# NM1500_v1 register map
File version: 1.0
Registers are 32-bit, read-write, reset 0x0 unless marked. A register's access mark holds for its fields unless they carry their own. Offsets are from the block's base; [hi:lo] are bit positions; {n}, {i} and the like mark numbered series; 'fields as' and 'values as' point back to an identical list.

## MDU0 — MDU Register Map
Base 0x401D0000
Same registers: MDU1 0x401D0400
0x00 Ia — Phase A Current Register, Represented in Q-15 Format
  [15:0] DATA — Motor Phase Current Data Register. This register stores the phase current data represented in Q-15 format. The MCU must update registers Ia, Ib and Ic in the beginning of a FOC process flow.
0x04 Ib — Phase A Current Register, Represented in Q-15 Format
  fields as Ia
0x08 Ic — Phase A Current Register, Represented in Q-15 Format
  fields as Ia
0x0C Ialfa — Clarke Transformation Output Register, the Current Along alpha-axis
  [15:0] DATA — Clarke Transformation Output Data Register. This data content is produced by Clarke Transformation function block and stored in Q-15 format. It is also writable by software.
0x10 Ibeta — Clarke Transformation Output Register, the Current Along alpha-axis
  fields as Ialfa
0x14 SIN — Trigonometric Value of SIN Register, Represented in Q-15 Format
  [15:0] DATA — Trigonometric Value of SIN / COS Data Register. The trigonometric value of SIN and COS, which is represented in Q-15 format, must be preset before operating Park and inverse Park transformation.
0x18 COS — Trigonometric Value of SIN Register, Represented in Q-15 Format
  fields as SIN
0x1C Id — Park Transformation Output Register, the Current Along d-axis.
  [15:0] DATA — Park Transformation Output Data Register. This data content is produced by Park Transformation function block and stored in Q-15 format. It is also writable by software.
0x20 Iq — Park Transformation Output Register, the Current Along d-axis.
  fields as Id
0x24 Id_CMD — PI_d Controller Command Input Register, Represented in Q-15 Format.
  [15:0] CMD — PI Controller Command Input Register. The register content stands for the PI controller command input. It must be normalized in Q-15 format.
0x28 Iq_CMD — PI_d Controller Command Input Register, Represented in Q-15 Format.
  fields as Id_CMD
0x2C KP_d — Parameter KP for PI_d Controller, Represented in 18-bit I2Q-15 (Q2.15) Format
  [17:0] DATA — PI Controller Parameter Register. The KP_d and KP_q stand for the proportional parameter of PI controller, the KI_d and KI_q stand for the integral parameter of PI controller. The register data value must be stored in Q-15 format.
0x30 KI_d — Parameter KP for PI_d Controller, Represented in 18-bit I2Q-15 (Q2.15) Format
  fields as KP_d
0x34 KP_q — Parameter KP for PI_d Controller, Represented in 18-bit I2Q-15 (Q2.15) Format
  fields as KP_d
0x38 KI_q — Parameter KP for PI_d Controller, Represented in 18-bit I2Q-15 (Q2.15) Format
  fields as KP_d
0x3C PI_dFW — PI_d Controller Feed Forward Data Register
  [15:0] DATA — PI Controller Feed Forward Data Register. Software presets the feed forward value of the PI controller in this register.
0x40 PI_qFW — PI_d Controller Feed Forward Data Register
  fields as PI_dFW
0x44 UI_d — D-axis I Control Output Data Register
  [15:0] DATA — Integral Controller Output Data Register. The PI function block content I (Integral) controller and P (Propotional) controller, and I controller output data will be used as the next PI control flow. Here is the register to save the output data of I controller and will update when PI controller finished once operation. Here, the register content is a Q-15 format value.
0x48 UI_q — D-axis I Control Output Data Register
  fields as UI_d
0x4C Vd — PI_d Controller Output of d-axis, Represented in Q-15 Format
  [15:0] DATA — PI Controller Output Data Register (Inverse Park Transformation Input). This data content is produced by PI controller function block and stored in Q-15 format. It is also writable by software.
0x50 Vq — PI_d Controller Output of d-axis, Represented in Q-15 Format
  fields as Vd
0x54 Valfa — Inverse Park Transformation Output, the Voltage Along the alpha-axis
  [15:0] DATA — Inverse Park Transformation Output Data Register. This data content is produced by inverse Park Transformation function block and stored in Q-15 format. It is also writable by software.
0x58 Vbeta — Inverse Park Transformation Output, the Voltage Along the alpha-axis
  fields as Valfa
{0x58+4i} Vref{i} (i=1..3) — Inverse Clarke Transformation Output Register
  [15:0] DATA — Inverse Clarke Transformation Output Data Register. This data content is produced by inverse Clarke Transformation function block and stored in Q-15 format. It is also writable by software.
0x68 SVPDATA0 — SVPWM output Data Register (it is an unsigned 16-bit value and denotes Taon time)
  [15:0] DATA — SVPWM Output Data Register. This data content is produced by SVPWM function block and stored in Q-15 format. It is also writable by software.
0x6C SVPDATA2 — SVPWM output Data Register (it is an unsigned 16-bit value and denotes Taon time)
  fields as SVPDATA0
0x70 SVPDATA4 — SVPWM output Data Register (it is an unsigned 16-bit value and denotes Taon time)
  fields as SVPDATA0
0x74 SVPDATA0N — An unsigned16-bit data Normalizes SVPDATA0 to PWMNORM and within the limit between PWMMAX and PWMMIN
  [15:0] DATA — Normalized SVPDATA Register. The SVPWM function block will normalizes the value of SVP0/2/4 to the range between 0000h and the value of PWMNORM and limit the PWM duty value within PWMMAX and PWMMIN. If SVPWM function block auto mode is active, each new SVPDATA0N/2N/4N will be reload to PWM unit 0 duty registers PWM0/2/4 after SVPWM operation is completed if PWMRUN and LOAD bits are enabled in PWM unit 0. Here, the register content is a 16-bit unsigned integer.
0x78 SVPDATA2N — An unsigned16-bit data Normalizes SVPDATA0 to PWMNORM and within the limit between PWMMAX and PWMMIN
  fields as SVPDATA0N
0x7C SVPDATA4N — An unsigned16-bit data Normalizes SVPDATA0 to PWMNORM and within the limit between PWMMAX and PWMMIN
  fields as SVPDATA0N
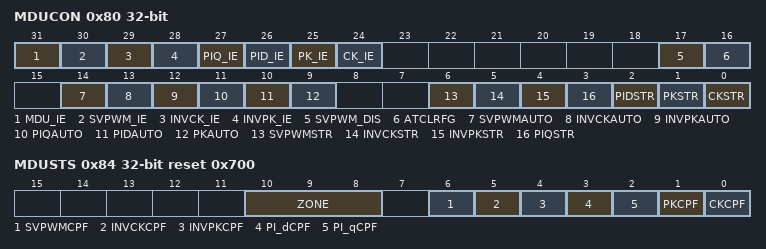
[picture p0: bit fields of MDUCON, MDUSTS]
0x80 MDUCON — Motor Driver Unit Control Register
  [31] MDU_IE — MDU Interrupt Enable Bit
    0=MDU interrupt Disabled; 1=MDU interrupt Enabled
  [30] SVPWM_IE — Clark Block Interrupt Enable Bit
    0=SVPWM block interrupt Disabled; 1=SVPWM block interrupt Enabled. Interrupt will generate if MDUINT_EN and SVPWM_IE is set to 1 and SVPWMCPF is set
  [29] INVCK_IE — Inv-Clark Block Interrupt Enable Bit
    0=Inv-Clark block interrupt Disabled; 1=Inv-Clark block interrupt Enabled
  [28] INVPK_IE — Inv-Park Block Interrupt Enable Bit
    0=Inv-Park block interrupt Disabled; 1=Inv-Park block interrupt Enabled
  [27] PIQ_IE — Q-axis PI Block Interrupt Enable Bit
    0=Q-axis PI controller block interrupt Disabled; 1=Q-axis PI controller block interrupt Enabled
  [26] PID_IE — D-axis PI Block Interrupt Enable Bit
    0=D-axis PI controller block interrupt Disabled; 1=D-axis PI controller block interrupt Enabled
  [25] PK_IE — Park Block Interrupt Enable Bit
    0=Park block interrupt Disabled; 1=Park block interrupt Enabled
  [24] CK_IE — Clark Block Interrupt Enable Bit
    0=Clark block interrupt Disabled; 1=Clark block interrupt Enabled
  [17] SVPWM_DIS — SVPWM Block Function Disable Bit
    0=SVPWM function block produces the Space Vector PWM timing for PWM duty registers; 1=SVPWM operation Disabled
  [16] ATCLRFG — Auto-Clear Flag Control Bit. When this bit is set to high, the complete flag of each function block in auto-mode is cleared automatically after SVPWM function block has updated PWM duty registers. The auto-clear flag function helps the FOC control flow runs smoothly without the need of software clearing flags.
    0=Auto-clear flag function Disabled; 1=Auto-clear flag function Enabled
  [14] SVPWMAUTO — SVPWM Auto-mode Enable Bit. Setting this bit will enable auto-mode of the function block. If the auto-mode is active, the SVPWM function block is allowed to accept the start trigger from Inverse Clarke block and SVPWM function proceeds completed, it will automatically update the duty registers in PWM unit0 and set the reload bit (LOAD).
    0=Auto-mode Disabled; 1=Auto-mode Enabled
  [13] INVCKAUTO — Inverse Clarke Transformation Auto-mode Enable Bit. Setting this bit will enable auto-mode of the function block. If the auto-mode is active, the current function block is allowed to accept the previous start trigger and will trigger the start bit of the next function block after current function is completed.
    0=Auto-mode Disabled; 1=Auto-mode Enabled
  [12] INVPKAUTO — Inverse Park Transformation Auto-mode Enable Bit. Setting this bit will enable auto-mode of the function block. If the auto-mode is active, the current function block is allowed to accept the previous start trigger and will trigger the start bit of the next function block after current function is completed.
    0=Auto-mode Disabled; 1=Auto-mode Enabled
  [11] PIQAUTO — D-axis PI Controller Auto-mode Enable Bit. Setting this bit will enable auto-mode of the function block. If the auto-mode is active, the current function block is allowed to accept the previous start trigger and will trigger the start bit of the next function block after current function is completed.
    0=Auto-mode Disabled; 1=Auto-mode Enabled
  [10] PIDAUTO — D-axis PI Controller Auto-mode Enable Bit. Setting this bit will enable auto-mode of the function block. If the auto-mode is active, the current function block is allowed to accept the previous start trigger and will trigger the start bit of the next function block after current function is completed.
    0=Auto-mode Disabled; 1=Auto-mode Enabled
  [9] PKAUTO — Park Transformation Auto-mode Enable Bit. Setting this bit will enable auto-mode of the function block. If the auto-mode is active, the current function block is allowed to accept the previous start trigger and will trigger the start bit of the next function block after current function is completed.
    0=Auto-mode Disabled; 1=Auto-mode Enabled
  [6] SVPWMSTR wo — SVPWM Start Bit (Write Only, Read 0). Setting this bit to high will start proceeding SVPWM timing calculating and it is automatically cleared when the process is completed by hardware. Writing it to 0 will stop and reset the function block.
    0=No action; 1=Start the process
  [5] INVCKSTR wo — Inverse Clarke Transformation Start Bit (Write Only, Read 0). Setting this bit to high will start proceeding Inverse Clarke Transformation and it is automatically cleared when the transform process is completed by hardware. Writing it to 0 will stop and reset the function block.
    0=No action; 1=Start the process
  [4] INVPKSTR wo — Inverse Park Transformation Start Bit (Write Only, Read 0). Setting this bit to high will start proceeding Inverse Park Transformation and it is automatically cleared when the transform process is completed by hardware. Writing it to 0 will stop and reset the function block.
    0=No action; 1=Start the process
  [3] PIQSTR wo — Q-axis PI Controller Start Bit (Write Only, Read 0). Setting this bit to high will start proceeding Q-axis PI Control and it is automatically cleared when the process is completed by hardware. Writing it to 0 will stop and reset the function block.
    0=No action; 1=Start the process
  [2] PIDSTR wo — D-axis PI Controller Start Bit (Write Only, Read 0). Setting this bit to high will start proceeding D-axis PI Control and it is automatically cleared when the process is completed by hardware. Writing it to 0 will stop and reset the function block.
    0=No action; 1=Start the process
  [1] PKSTR wo — Park Transformation Start Bit (Write Only, Read 0). Setting this bit to high will start proceeding Park Transformation and it is automatically cleared when the transform process is completed by hardware. Writing it to 0 will stop and reset the function block.
    0=No action; 1=Start the process
  [0] CKSTR wo — Clarke Transformation Start Bit (Write Only, Read 0). Setting this bit to high will start proceeding Clarke Transformation and it is automatically cleared when the transform process is completed by hardware. Writing it to 0 will stop and reset the function block.
    0=No action; 1=Start the process
0x84 MDUSTS reset 0x700 — Motor Driver Unit Status Register
  [10:8] ZONE — Zone Number Indicator. A 360 degree space is equally divided into six zones where each zone is with 60 degree space. The SVPWM function block will internally produce the zone number during the operation which indicates the which zone the motor electric angle stays in the moment.
  [6] SVPWMCPF — SVPWM Complete Flag. When the function block completes the process, the corresponding complete flag will be set by hardware. This flag can be cleared by a writing one to itself. Note: If both the control bits ATCLRFG (Auto-clear flag control bit) and SVPWMAUTO (Auto-mode enable bit) are set to high, the complete flag is cleared automatically after SVPWM function block has set PWM LOAD bit to high.
  [5] INVCKCPF — Inverse Clarke Transformation Complete Flag. When the function block completes the process, the corresponding complete flag will be set by hardware. This flag can be cleared by a writing one to itself. Note: If both the control bits ATCLRFG (Auto-clear flag control bit) and INVCKAUTO (Auto-mode enable bit) are set to high, the complete flag is cleared automatically after SVPWM function block has set PWM LOAD bit to high.
  [4] INVPKCPF — Inverse Park Transformation Complete Flag. When the function block completes the process, the corresponding complete flag will be set by hardware. This flag can be cleared by a writing one to itself. Note: If both the control bits ATCLRFG (Auto-clear flag control bit) and INVPKAUTO (Auto-mode enable bit) are set to high, the complete flag is cleared automatically after SVPWM function block has set PWM LOAD bit to high.
  [3] PI_dCPF — PI_d Controller Complete Flag. When the function block completes the process, the corresponding complete flag will be set by hardware. This flag can be cleared by a writing one to itself. Note: If both the control bits ATCLRFG (Auto-clear flag control bit) and PI_dAUTO (Auto-mode enable bit) are set to high, the complete flag is cleared automatically after SVPWM function block has set PWM LOAD bit to high.
  [2] PI_qCPF — PI_q Controller Complete Flag. When the function block completes the process, the corresponding complete flag will be set by hardware. This flag can be cleared by a writing one to itself. Note: If both the control bits ATCLRFG (Auto-clear flag control bit) and PI_qAUTO (Auto-mode enable bit) are set to high, the complete flag is cleared automatically after SVPWM function block has set PWM LOAD bit to high.
  [1] PKCPF — Park Transformation Complete Flag. When the function block completes the process, the corresponding complete flag will be set by hardware. This flag can be cleared by a writing one to itself. Note: If both the control bits ATCLRFG (Auto-clear flag control bit) and PKAUTO (Auto-mode enable bit) are set to high, the complete flag is cleared automatically after SVPWM function block has set PWM LOAD bit to high.
  [0] CKCPF — Clarke Transformation Complete Flag. When the function block completes the process, the corresponding complete flag will be set by hardware. This flag can be cleared by a writing one to itself. Note: If both the control bits ATCLRFG (Auto-clear flag control bit) and CKAUTO (Auto-mode enable bit) are set to high, the complete flag is cleared automatically after SVPWM function block has set PWM LOAD bit to high.
0x100 PI_dMAX reset 0x7FFF — Maximum limit value of PI_d Controller in Q-15 Format
  [15:0] MAX — Maximum Limit of PI Controller and I Controller Output. The 16-bit value represented in Q-15 format limits the maximum value of the PI controller and I controller output.
0x104 PI_dMIN reset 0x8000 — Minimum limit value of PI_d Controller in Q-15 Format
  [15:0] MIN — Minimum Limit of PI Controller and I Controller Output. The 16-bit value represented in Q-15 format limits the minimum value of the PI controller and I controller output.
0x108 PI_qMAX reset 0x7FFF — Maximum limit value of PI_d Controller in Q-15 Format
  fields as PI_dMAX
0x10C PI_qMIN reset 0x8000 — Minimum limit value of PI_d Controller in Q-15 Format
  fields as PI_dMIN
0x110 I_dMAX reset 0x7FFF — Maximum limit value of integral_d Controller in Q-15 Format
  [15:0] MAX — Maximum Limit of PI Controller and I Controller Output. The 16-bit value represented in Q-15 format limits the maximum value of the integral controller output.
0x114 I_dMIN reset 0x8000 — Minimum limit value of integral_d Controller in Q-15 Format
  [15:0] MIN — Minimum Limit of PI Controller and I Controller Output. The 16-bit value represented in Q-15 format limits the minimum value of the integral controller output.
0x118 I_qMAX reset 0x7FFF — Maximum limit value of integral_d Controller in Q-15 Format
  fields as I_dMAX
0x11C I_qMIN reset 0x8000 — Minimum limit value of integral_d Controller in Q-15 Format
  fields as I_dMIN
0x120 Vd_In ro — Inverse Park Transformation Input of d_axis represented in Q-15 Format
  [15:0] DATA — Inverse Park Transformation Input Data (Read Only). This data content is produced by the PI controller with maximum and minimum limit operation and stored in Q-15 format. It is a read only register
0x124 Vq_In ro — Inverse Park Transformation Input of d_axis represented in Q-15 Format
  fields as Vd_In
0x128 PWMNORM — An Unsigned 16-bit PWM Normalization Value
  [15:0] PWMNORM — PWM Normalization Data. The SVPWM function block will normalize the value of SVP0/2/4 to the range between 0000h and the value of PWMNORM and limit the PWM duty value within PWMMAX and PWMMIN. Here, the register content is a 16-bit unsigned integer.
0x12C PWMMAX reset 0xFFFF — An unsigned 16-bit Maximum Limit Value of SVPWM Output
  [15:0] PWMMAX — Maximum Limit of SVPWM Output Data Register. The SVPWM function block will normalizes the value of SVP0/2/4 to the range between 0000h and the value of PWMNORM and limit the PWM duty value within PWMMAX and PWMMIN. Here, the register content is a 16-bit unsigned integer.
0x130 PWMMIN — An unsigned 16-bit Minimum Limit Value of SVPWM Output
  [15:0] PWMMIN — Maximum Limit of SVPWM Output Data Register. The SVPWM function block will normalize the value of SVP0/2/4 to the range between 0000h and the value of PWMNORM and limit the PWM duty value within PWMMAX and PWMMIN. Here, the register content is a 16-bit unsigned integer.
0x134 Id_Err ro — Error of Id current = Id_CMD - Id; Read only
0x138 Iq_Err ro — Error of Id current = Iq_CMD - Iq; Read only.
